# ECM3531 register map
Vendor: EtaCompute; Series: ECM35xx; File version: 1.0.0
CPU: CM3 r1p1, little endian, MPU, no FPU, 3 interrupt priority bits
Registers are 32-bit, read-write, reset 0x0 unless marked. A register's access mark holds for its fields unless they carry their own. Offsets are from the block's base; [hi:lo] are bit positions; {n}, {i} and the like mark numbered series.

## PWM — The PWM module contains four PWM generators. The PWM generators are configured with a command FIFO which sets their config, period, pulse start, and pulse end internal registers. A channel multiplexer steers PWM signals to any of the 16 output pins. The PWM supports synchronous channel changes to avoid glitches on the output.
Base 0x50000000
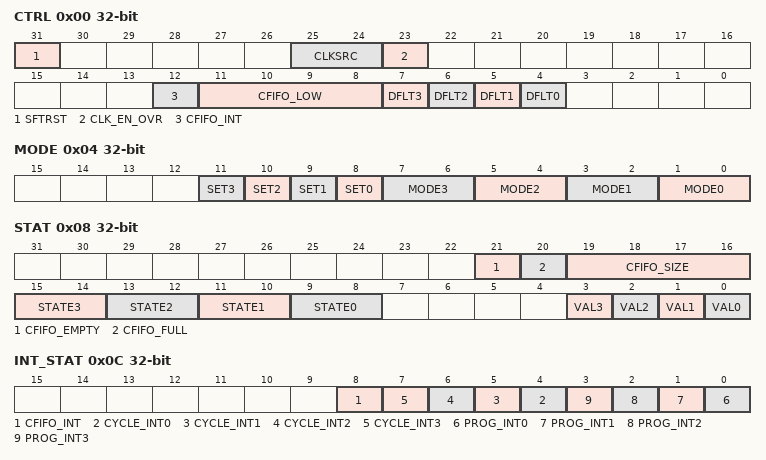
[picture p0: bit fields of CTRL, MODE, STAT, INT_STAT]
0x00 CTRL — Control register for the PWM peripheral.
  [31] SFTRST — Soft reset which resets the entire PWM to its POR state.
    1=RST (Reset.)
  [25:24] CLKSRC — Counter reference for the PWM generators. The registers always run on the 8MHz clock.
    0=32KHZ (32KHz oscillator.); 1=1MHZ (1MHz oscillator.); 2=8MHZ (8MHz oscillator.)
  [23] CLK_EN_OVR — Force the clock enable for this module ON to prevent clock gating at the HFO. Intended for debug purposes.
    1=ENABLE (Prevent HFO clock gating.); 0=DISABLE (Allow HFO clock gating when block is inactive.)
  [12] CFIFO_INT — The Command FIFO low interrupt enable.
    1=EN (Enable.); 0=DIS (Disable.)
  [11:8] CFIFO_LOW — If enabled, the Command FIFO will trigger an interrupt at a level less than or equal to this value.
  [n+4] DFLT{n} (n=0..3) — PWM{n}s default drive when idle.
    1=HI (High.); 0=LO (Low.)
0x04 MODE — Start/stop register for PWM. Simultaneously write multiple fields to start PWMs in lockstep.
  [n+8] SET{n} wo (n=0..3) — Apply PWM mode.
    1=SET (Set PWM to MODE.)
  [2n+1:2n] MODE{n} wo (n=0..3) — Set PWM mode.
    3=START (Start PWM.); 2=PSTOP (Stop PWM after the current program.); 1=CSTOP (Stop PWM after the current cycle.); 0=ISTOP (Stop PWM immediately.)
0x08 STAT — PWM status register.
  [21] CFIFO_EMPTY ro — Indicates if the Command FIFO is empty.
    1=EMPTY
  [20] CFIFO_FULL ro — Indicates if the Command FIFO is full.
    1=FULL
  [19:16] CFIFO_SIZE ro — Current consumption of the Command FIFO from 0 -> 15. Check CFIFO_FULL to see if consumption is 16.
  [2n+9:2n+8] STATE{n} ro (n=0..3) — Current running state of the PWMs.
    3=RUN (PWM Running.); 2=PSTOP (PWM will stop after the current program.); 1=CSTOP (PWM will stop after the current cycle.); 0=STOP (PWM stopped.)
  [n] VAL{n} ro (n=0..3) — Current value driven by the PWM{n} module.
    1=HI (High.); 0=LO (Low.)
0x0C INT_STAT — WARNING: READ SIDE EFFECT. Interrupt status register. Reading interrupt status resets any pending interrupt requests.
  [all] fields
    1=INT (Interrupt asserted.)
  [8] CFIFO_INT ro — Indicates if the Command FIFO has triggered a low interrupt.
  [n+4] CYCLE_INT{n} ro (n=0..3) — Indicates if PWM{n} has triggered a cycle interrupt.
  [n] PROG_INT{n} ro (n=0..3) — Indicates if PWM{n} has triggered a program interrupt.
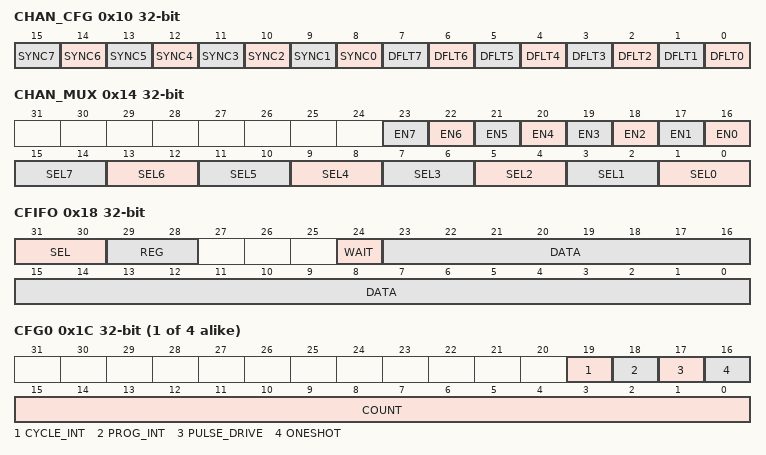
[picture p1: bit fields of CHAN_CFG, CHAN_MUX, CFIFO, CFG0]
0x10 CHAN_CFG — PWM channel configuration register.
  [n+8] SYNC{n} (n=0..7) — Synchronous transition bit. Disable for instantaneous MUX changes, otherwise the MUX will wait for current cycle to end, disable, then wait for next cycle to end before enabling.
    1=EN (Enable.); 0=DIS (Disable.)
  [n] DFLT{n} (n=0..7) — Default drive value when channel is disabled.
    1=HI (High.); 0=LO (Low.)
0x14 CHAN_MUX — Selects which PWM to assign to the output channels.
  [n+16] EN{n} (n=0..7) — Channel enable bit.
    1=EN (Enable.); 0=DIS (Disable.)
  [2n+1:2n] SEL{n} (n=0..7) — PWM to assign to channel #{n}.
    {v}=PWM{v} (Assign PWM{v} to channel.) (v=0..3)
0x18 CFIFO — Writes a command into the command FIFO. Writing the MSbyte commits all four bytes to the FIFO. Reading this register returns the next command waiting to come out of the FIFO. The WAIT field prevents the command at the top of the FIFO from being popped until the end of the currently running PWM program.
  [31:30] SEL wo — PWM generator selected for this command.
    {v}=PWM{v} (Write to PWM{v}.) (v=0..3)
  [29:28] REG wo — PWM register selected for this command.
    0=CFG (Write to CFG register.); 1=PER (Write to PER register.); 2=PSTRT (Write to PSTRT register.); 3=PEND (Write to PEND register.)
  [24] WAIT wo — Write this command after the currently running program has finished.
    1=EN (Enable.); 0=DIS (Disable.)
  [23:0] DATA wo — PWM register data. Derive format from the relevant CFG, PER, PSTRT, and PEND registers. There are helper enumerations below for setting bits in a CFG command.
    0x80000=CYCLE_INT ((For CFG command) Set bit-19 to trigger interrupt at the end of each PWM cycle.); 0x40000=PROG_INT ((For CFG command) Set bit-18 bit to trigger interrupt at the end of this program.); 0x20000=PULSE_DRIVE ((For CFG command) Set bit-17 for standard pulse output drive (Pulse is high), otherwise pulse is inverted (Pulse is low).); 0x10000=ONESHOT ((For CFG command) Set bit-16 to do only COUNT pulses and then stop. Disable this bit to run forever. CFIFO WAIT command will always load after COUNT pulses regardless of oneshot state.)
{0x1C+4i} CFG{i} (i=0..3) — PWM count and configuration register.
  [19] CYCLE_INT ro — Trigger interrupt at the end of each PWM cycle.
    1=EN (Enable.); 0=DIS (Disable.)
  [18] PROG_INT ro — Trigger interrupt at the end of each program.
    1=EN (Enable.); 0=DIS (Disable.)
  [17] PULSE_DRIVE ro — PWM pulse drive polarity.
    1=HI (High.); 0=LO (Low.)
  [16] ONESHOT ro — Enable to do only COUNT pulses and then stop. Disable to run forever. CFIFO WAIT command will always load after COUNT pulses regardless of oneshot state.
    1=EN (Enable.); 0=DIS (Disable.)
  [15:0] COUNT ro — Number of PWM cycles (N-1 PWM cycles).
{0x2C+4i} PER{i} (i=0..3) — PWM period register.
  [23:0] PER ro — Period of PWM (N-1 clock cycles).
{0x3C+4i} PSTRT{i} (i=0..3) — PWM pulse start register.
  [23:0] PSTRT ro — Pulse start of PWM period.
{0x4C+4i} PEND{i} (i=0..3) — PWM pulse end register.
  [23:0] PEND ro — Pulse end of PWM period.
0x5C DBG_READ_ONLY — This register provides a read only test value for checking IP connectivity to AHB.
  [31:0] VALUE ro — First 7 numbers in the Fibonacci sequence.
